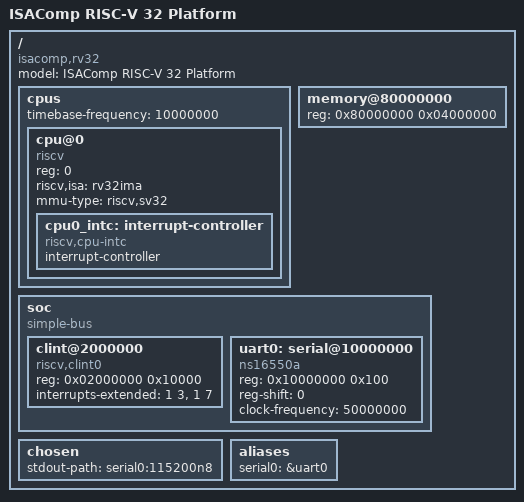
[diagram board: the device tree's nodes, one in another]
/dts-v1/;

/ {
	#address-cells = <1>;
	#size-cells = <1>;
	compatible = "isacomp,rv32";
	model = "ISAComp RISC-V 32 Platform";

	cpus {
		#address-cells = <1>;
		#size-cells = <0>;
		timebase-frequency = <10000000>;

		cpu@0 {
			device_type = "cpu";
			reg = <0>;
			compatible = "riscv";
			riscv,isa = "rv32ima";
			mmu-type = "riscv,sv32";

			cpu0_intc: interrupt-controller {
				#interrupt-cells = <1>;
				interrupt-controller;
				compatible = "riscv,cpu-intc";
				phandle = <1>;
			};
		};
	};

	memory@80000000 {
		device_type = "memory";
		reg = <0x80000000 0x04000000>;
	};

	soc {
		#address-cells = <1>;
		#size-cells = <1>;
		compatible = "simple-bus";
		ranges;

		clint@2000000 {
			compatible = "riscv,clint0";
			reg = <0x02000000 0x10000>;
			interrupts-extended = <1 3>, <1 7>;
		};

		uart0: serial@10000000 {
			compatible = "ns16550a";
			reg = <0x10000000 0x100>;
			reg-shift = <0>;
			clock-frequency = <50000000>;
		};
	};

	chosen {
		stdout-path = "serial0:115200n8";
	};

	aliases {
		serial0 = &uart0;
	};
};
